# M4KN register map
File version: 0.1
Registers are 32-bit, read-write, reset 0x0 unless marked. A register's access mark holds for its fields unless they carry their own. Offsets are from the block's base; [hi:lo] are bit positions; {n}, {i} and the like mark numbered series.

## UART0 — Asynchronous Serial Communication Circuit (UART)
Base 0x400CE000
Same registers: UART1 0x400CE400, UART2 0x400CE800, UART3 0x400CEC00
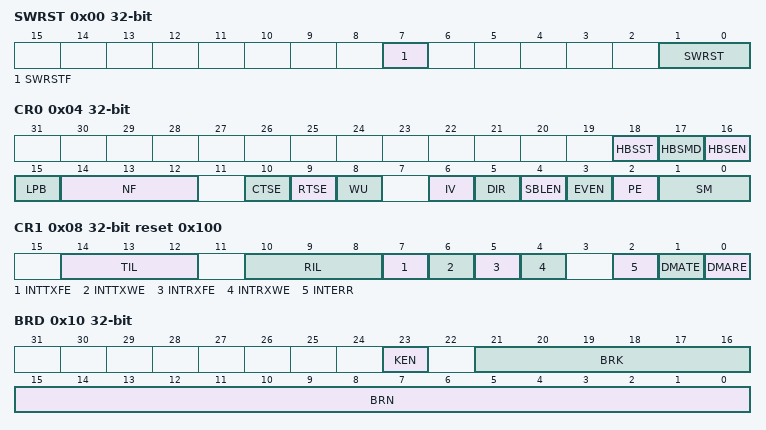
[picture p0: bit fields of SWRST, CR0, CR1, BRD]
0x00 SWRST — UART Software Reset Register
  [7] SWRSTF ro, [1:0] SWRST wo
0x04 CR0 — UART Control Register 0
  [18] HBSST, [17] HBSMD, [16] HBSEN, [15] LPB, [14:12] NF, [10] CTSE, [9] RTSE, [8] WU, [6] IV, [5] DIR, [4] SBLEN, [3] EVEN, [2] PE, [1:0] SM
0x08 CR1 reset 0x100 — UART Control Register 1
  [14:12] TIL, [10:8] RIL, [7] INTTXFE, [6] INTTXWE, [5] INTRXFE, [4] INTRXWE, [2] INTERR, [1] DMATE, [0] DMARE
0x0C CLK — UART Clock Control Register
  [7:4] PRSEL
0x10 BRD — UART Baud Rate Register
  [23] KEN, [21:16] BRK, [15:0] BRN
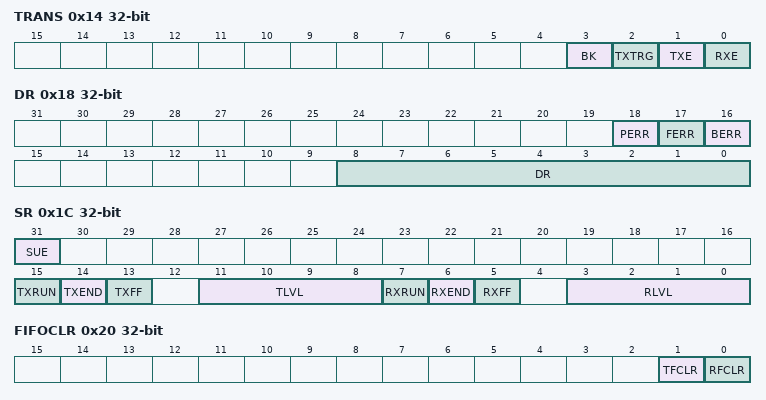
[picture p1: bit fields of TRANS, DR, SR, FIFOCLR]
0x14 TRANS — UART Transfer Enable Register
  [3] BK, [2] TXTRG, [1] TXE, [0] RXE
0x18 DR (reset mask 0xFFFFFE00) — UART Data Register
  [18] PERR ro, [17] FERR ro, [16] BERR ro, [8:0] DR
0x1C SR — UART Status Register
  [31] SUE ro, [15] TXRUN ro, [14] TXEND, [13] TXFF, [11:8] TLVL ro, [7] RXRUN ro, [6] RXEND, [5] RXFF, [3:0] RLVL ro
0x20 FIFOCLR wo — UART FIFO Clear Register
  [1] TFCLR, [0] RFCLR
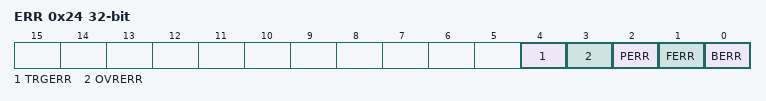
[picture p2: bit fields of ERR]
0x24 ERR — UART Error Register
  [4] TRGERR, [3] OVRERR, [2] PERR, [1] FERR, [0] BERR

## I2C0 — I2C Interface (I2C)
Base 0x400D1000
Same registers: I2C1 0x400D2000
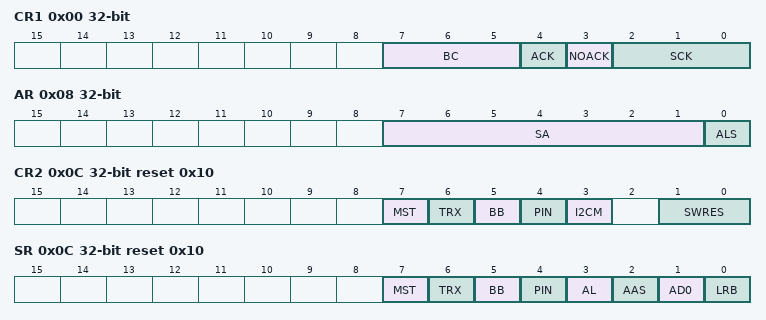
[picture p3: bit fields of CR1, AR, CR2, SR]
0x00 CR1 — I2C Control Register 1
  [7:5] BC, [4] ACK, [3] NOACK, [2:0] SCK
0x04 DBR — Data Buffer Register
  [7:0] DB
0x08 AR — Bus address Register
  [7:1] SA, [0] ALS
0x0C CR2 wo reset 0x10 — Control Register 2
  [7] MST, [6] TRX, [5] BB, [4] PIN, [3] I2CM, [1:0] SWRES
0x0C SR ro reset 0x10 — Status Register
  [7] MST, [6] TRX, [5] BB, [4] PIN, [3] AL, [2] AAS, [1] AD0, [0] LRB
0x10 PRS reset 0x1 — Prescaler clcok setting Register
  [4:0] PRSCK
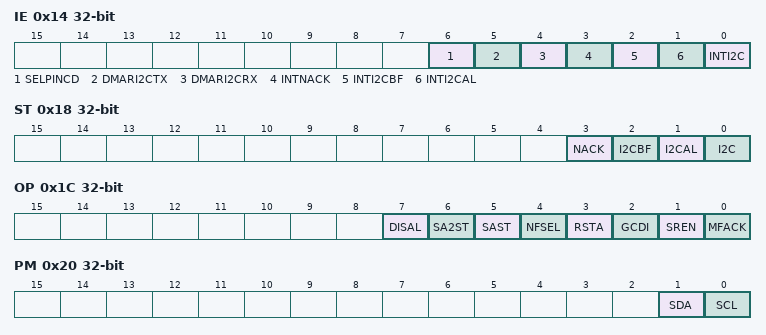
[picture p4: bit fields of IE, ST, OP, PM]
0x14 IE — Interrupt Enable Register
  [6] SELPINCD, [5] DMARI2CTX, [4] DMARI2CRX, [3] INTNACK, [2] INTI2CBF, [1] INTI2CAL, [0] INTI2C
0x18 ST — Interrupt Register
  [3] NACK, [2] I2CBF, [1] I2CAL, [0] I2C
0x1C OP — Optiononal Function register
  [7] DISAL, [6] SA2ST ro, [5] SAST ro, [4] NFSEL, [3] RSTA, [2] GCDI, [1] SREN, [0] MFACK
0x20 PM ro — Bus Monitor register
  [1] SDA, [0] SCL
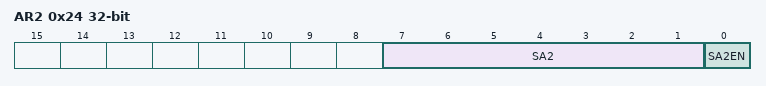
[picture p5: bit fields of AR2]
0x24 AR2 — Second Slave address register
  [7:1] SA2, [0] SA2EN

## PA — Port A
Base 0x400E0000
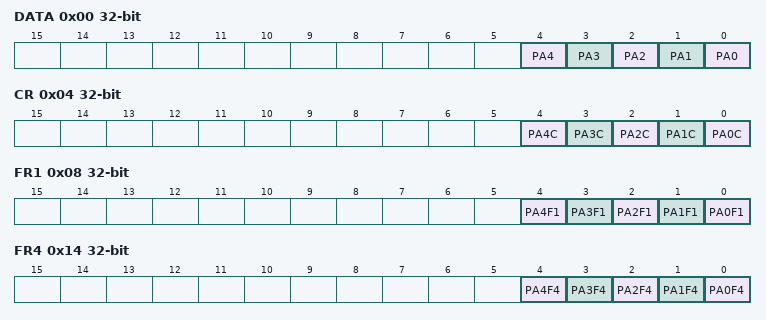
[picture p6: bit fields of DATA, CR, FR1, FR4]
0x00 DATA — Port A Data Register
  [n] PA{n} (n=0..4)
0x04 CR — Port A Output Control Register
  [n] PA{n}C (n=0..4)
0x08 FR1 — Port A Function Register 1
  [n] PA{n}F1 (n=0..4)
0x14 FR4 — Port A Function Register 4
  [n] PA{n}F4 (n=0..4)
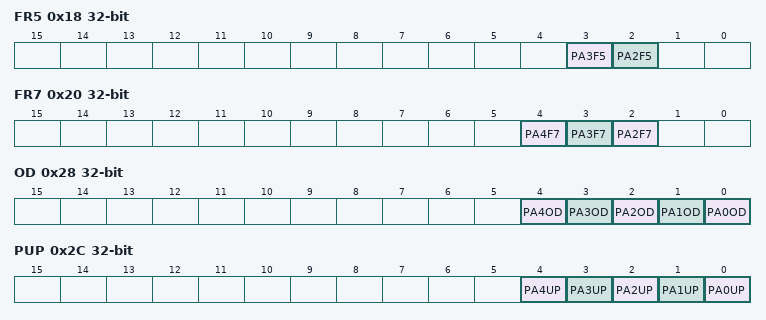
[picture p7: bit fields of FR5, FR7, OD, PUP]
0x18 FR5 — Port A Function Register 5
  [3] PA3F5, [2] PA2F5
0x1C FR6 — Port A Function Register 6
  [2] PA2F6
0x20 FR7 — Port A Function Register 7
  [4] PA4F7, [3] PA3F7, [2] PA2F7
0x28 OD — Port A Open Drain Control Register
  [n] PA{n}OD (n=0..4)
0x2C PUP — Port A Pull-up Control Register
  [n] PA{n}UP (n=0..4)
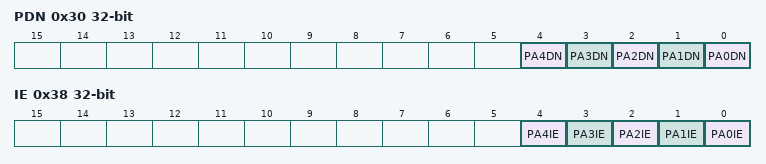
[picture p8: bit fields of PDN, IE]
0x30 PDN — Port A Pull-down Control Register
  [n] PA{n}DN (n=0..4)
0x38 IE — Port A Input Control Register
  [n] PA{n}IE (n=0..4)

## PB — Port B
Base 0x400E0100
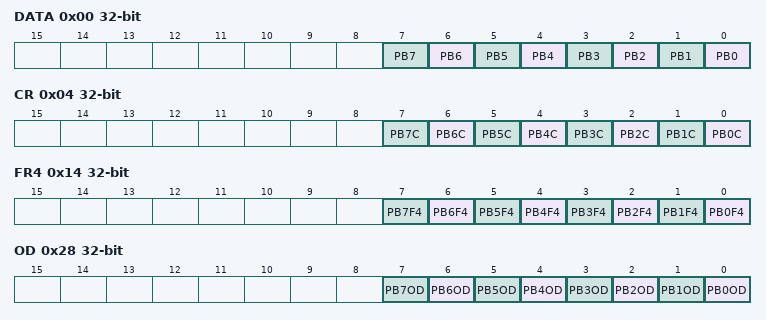
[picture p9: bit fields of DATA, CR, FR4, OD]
0x00 DATA — Port B Data Register
  [n] PB{n} (n=0..7)
0x04 CR — Port B Output Control Register
  [n] PB{n}C (n=0..7)
0x14 FR4 — Port B Function Register 4
  [n] PB{n}F4 (n=0..7)
0x18 FR5 — Port B Function Register 5
  [7] PB7F5
0x28 OD — Port B Open Drain Control Register
  [n] PB{n}OD (n=0..7)
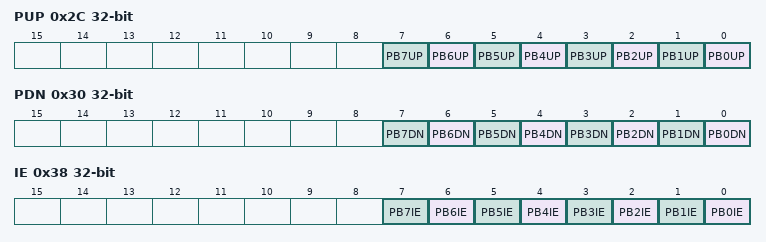
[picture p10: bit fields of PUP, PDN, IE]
0x2C PUP — Port B Pull-up Control Register
  [n] PB{n}UP (n=0..7)
0x30 PDN — Port B Pull-down Control Register
  [n] PB{n}DN (n=0..7)
0x38 IE — Port B Input Control Register
  [n] PB{n}IE (n=0..7)

## PC — Port C
Base 0x400E0200
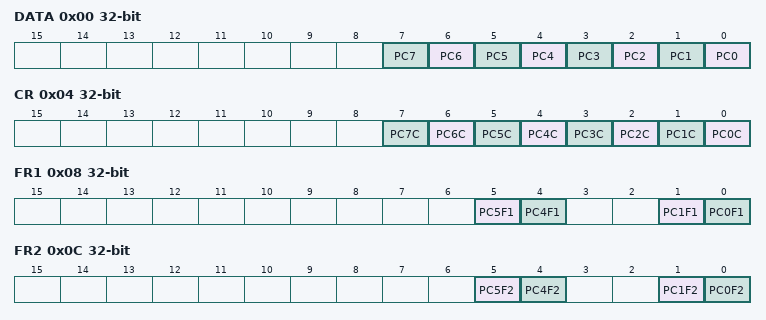
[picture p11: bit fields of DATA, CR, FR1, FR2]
0x00 DATA — Port C Data Register
  [n] PC{n} (n=0..7)
0x04 CR — Port C Output Control Register
  [n] PC{n}C (n=0..7)
0x08 FR1 — Port C Function Register 1
  [5] PC5F1, [4] PC4F1, [1] PC1F1, [0] PC0F1
0x0C FR2 — Port C Function Register 2
  [5] PC5F2, [4] PC4F2, [1] PC1F2, [0] PC0F2
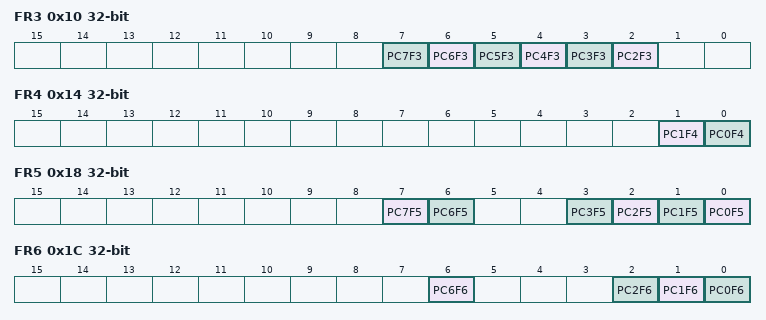
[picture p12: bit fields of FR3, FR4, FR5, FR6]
0x10 FR3 — Port C Function Register 3
  [n] PC{n}F3 (n=2..7)
0x14 FR4 — Port C Function Register 4
  [1] PC1F4, [0] PC0F4
0x18 FR5 — Port C Function Register 5
  [7] PC7F5, [6] PC6F5, [n] PC{n}F5 (n=0..3)
0x1C FR6 — Port C Function Register 6
  [6] PC6F6, [2] PC2F6, [1] PC1F6, [0] PC0F6
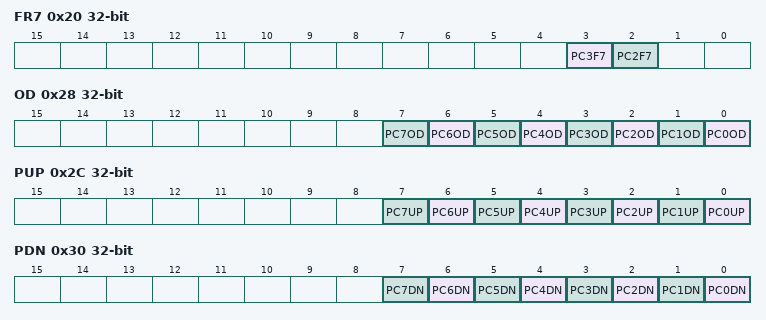
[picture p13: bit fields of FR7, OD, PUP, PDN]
0x20 FR7 — Port C Function Register 7
  [3] PC3F7, [2] PC2F7
0x28 OD — Port C Open Drain Control Register
  [n] PC{n}OD (n=0..7)
0x2C PUP — Port C Pull-up Control Register
  [n] PC{n}UP (n=0..7)
0x30 PDN — Port C Pull-down Control Register
  [n] PC{n}DN (n=0..7)
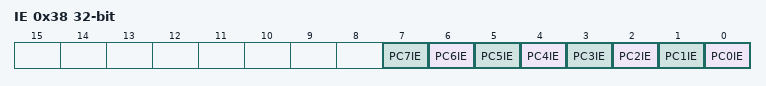
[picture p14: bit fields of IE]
0x38 IE — Port C Input Control Register
  [n] PC{n}IE (n=0..7)
